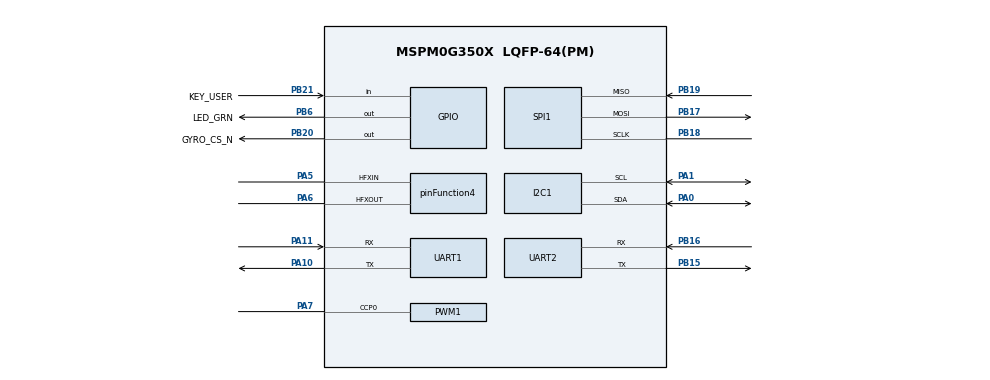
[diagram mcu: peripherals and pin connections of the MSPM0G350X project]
/**
 *
 * @cliArgs --device "MSPM0G350X" --part "Default" --package "LQFP-64(PM)" --product "mspm0_sdk@2.10.00.04"
 * @versions {"tool":"1.28.0+4712"}
 */

/**
 * Import the modules used in this configuration.
 */
const GPIO          = scripting.addModule("/ti/driverlib/GPIO", {}, false);
const GPIO1         = GPIO.addInstance();
const GPIO2         = GPIO.addInstance();
const GPIO3         = GPIO.addInstance();
const I2C           = scripting.addModule("/ti/driverlib/I2C", {}, false);
const I2C1          = I2C.addInstance();
const MATHACL       = scripting.addModule("/ti/driverlib/MATHACL");
const PWM           = scripting.addModule("/ti/driverlib/PWM", {}, false);
const PWM1          = PWM.addInstance();
const SPI           = scripting.addModule("/ti/driverlib/SPI", {}, false);
const SPI1          = SPI.addInstance();
const SYSCTL        = scripting.addModule("/ti/driverlib/SYSCTL");
const SYSTICK       = scripting.addModule("/ti/driverlib/SYSTICK");
const UART          = scripting.addModule("/ti/driverlib/UART", {}, false);
const UART1         = UART.addInstance();
const UART2         = UART.addInstance();
const ProjectConfig = scripting.addModule("/ti/project_config/ProjectConfig");

/**
 * Write custom configuration values to the imported modules.
 */
const divider9       = system.clockTree["UDIV"];
divider9.divideValue = 2;

const mux2       = system.clockTree["CANCLKMUX"];
mux2.inputSelect = "CANCLKMUX_PLLCLK1_OUT";

const mux4       = system.clockTree["EXHFMUX"];
mux4.inputSelect = "EXHFMUX_XTAL";

const mux8       = system.clockTree["HSCLKMUX"];
mux8.inputSelect = "HSCLKMUX_SYSPLL2X";

const mux10       = system.clockTree["MFPCLKMUX"];
mux10.inputSelect = "MFPCLKMUX_HFCLK";

const mux12       = system.clockTree["SYSPLLMUX"];
mux12.inputSelect = "zSYSPLLMUX_HFCLK";

const pinFunction4                        = system.clockTree["HFXT"];
pinFunction4.inputFreq                    = 40;
pinFunction4.enable                       = true;
pinFunction4.HFCLKMonitor                 = true;
pinFunction4.HFXTStartup                  = 255;
pinFunction4.peripheral.hfxInPin.$assign  = "PA5";
pinFunction4.peripheral.hfxOutPin.$assign = "PA6";

GPIO1.port                           = "PORTB";
GPIO1.$name                          = "GPIO_GRP_LEDS";
GPIO1.portSegment                    = "Lower";
GPIO1.associatedPins.create(2);
GPIO1.associatedPins[0].$name        = "LED_GRN";
GPIO1.associatedPins[0].initialValue = "SET";
GPIO1.associatedPins[0].ioStructure  = "SD";
GPIO1.associatedPins[0].assignedPin  = "6";
GPIO1.associatedPins[0].pin.$assign  = "PB6";
GPIO1.associatedPins[1].$name        = "LED_RED";
GPIO1.associatedPins[1].initialValue = "SET";
GPIO1.associatedPins[1].ioStructure  = "SD";
GPIO1.associatedPins[1].assignedPin  = "7";

const Board = scripting.addModule("/ti/driverlib/Board", {}, false);

GPIO2.port                          = "PORTB";
GPIO2.$name                         = "GPIO_GRP_KEY";
GPIO2.portSegment                   = "Upper";
GPIO2.associatedPins[0].$name       = "KEY_USER";
GPIO2.associatedPins[0].direction   = "INPUT";
GPIO2.associatedPins[0].interruptEn = true;
GPIO2.associatedPins[0].polarity    = "RISE_FALL";
GPIO2.associatedPins[0].assignedPin = "21";
GPIO2.associatedPins[0].pin.$assign = "PB21";

GPIO3.port                           = "PORTB";
GPIO3.$name                          = "GPIO_GRP_GYRO";
GPIO3.portSegment                    = "Upper";
GPIO3.associatedPins[0].$name        = "GYRO_CS_N";
GPIO3.associatedPins[0].initialValue = "SET";
GPIO3.associatedPins[0].assignedPin  = "20";
GPIO3.associatedPins[0].pin.$assign  = "PB20";

I2C1.$name                             = "I2C_TEMP";
I2C1.basicEnableController             = true;
I2C1.advControllerTXFIFOTRIG           = "BYTES_1";
I2C1.intController                     = ["ARBITRATION_LOST","NACK","RXFIFO_TRIGGER","RX_DONE","TX_DONE"];
I2C1.peripheral.$assign                = "I2C0";
I2C1.peripheral.sdaPin.$assign         = "PA0";
I2C1.peripheral.sclPin.$assign         = "PA1";
I2C1.sdaPinConfig.$name                = "ti_driverlib_gpio_GPIOPinGeneric0";
I2C1.sdaPinConfig.hideOutputInversion  = scripting.forceWrite(false);
I2C1.sdaPinConfig.onlyInternalResistor = scripting.forceWrite(false);
I2C1.sdaPinConfig.passedPeripheralType = scripting.forceWrite("Digital");
I2C1.sclPinConfig.$name                = "ti_driverlib_gpio_GPIOPinGeneric1";
I2C1.sclPinConfig.hideOutputInversion  = scripting.forceWrite(false);
I2C1.sclPinConfig.onlyInternalResistor = scripting.forceWrite(false);
I2C1.sclPinConfig.passedPeripheralType = scripting.forceWrite("Digital");

PWM1.$name                              = "PWM_OUTPUT";
PWM1.clockSource                        = "BUSCLK";
PWM1.clockDivider                       = 1;
PWM1.clockPrescale                      = 1;
PWM1.timerCount                         = 2000;
PWM1.pwmMode                            = "EDGE_ALIGN";
PWM1.ccIndex                            = [0];
PWM1.enableShadowLoad                   = false;
PWM1.timerStartTimer                    = false;
PWM1.peripheral.$assign                 = "TIMG8";
PWM1.peripheral.ccp0Pin.$assign         = "PA7";
PWM1.ccp0PinConfig.$name                = "ti_driverlib_gpio_GPIOPinGeneric10";
PWM1.PWM_CHANNEL_0.$name                = "ti_driverlib_pwm_PWMTimerCC0";
PWM1.PWM_CHANNEL_0.dutyCycle            = 0;

SPI1.$name                              = "SPI_GYRO";
SPI1.targetBitRate                      = 1000000;
SPI1.frameFormat                        = "MOTO3";
SPI1.chipSelect                         = [];
SPI1.sclkPinConfig.$name                = "ti_driverlib_gpio_GPIOPinGeneric2";
SPI1.sclkPinConfig.direction            = scripting.forceWrite("OUTPUT");
SPI1.sclkPinConfig.onlyInternalResistor = scripting.forceWrite(false);
SPI1.sclkPinConfig.passedPeripheralType = scripting.forceWrite("Digital");
SPI1.mosiPinConfig.$name                = "ti_driverlib_gpio_GPIOPinGeneric3";
SPI1.mosiPinConfig.direction            = scripting.forceWrite("OUTPUT");
SPI1.mosiPinConfig.hideOutputInversion  = scripting.forceWrite(false);
SPI1.mosiPinConfig.onlyInternalResistor = scripting.forceWrite(false);
SPI1.mosiPinConfig.passedPeripheralType = scripting.forceWrite("Digital");
SPI1.misoPinConfig.$name                = "ti_driverlib_gpio_GPIOPinGeneric4";
SPI1.misoPinConfig.onlyInternalResistor = scripting.forceWrite(false);
SPI1.misoPinConfig.passedPeripheralType = scripting.forceWrite("Digital");
SPI1.misoPinConfig.enableConfig         = true;
SPI1.misoPinConfig.internalResistor     = "PULL_UP";
SPI1.peripheral.$assign                 = "SPI0";
SPI1.peripheral.sclkPin.$assign         = "PB18";
SPI1.peripheral.mosiPin.$assign         = "PB17";
SPI1.peripheral.misoPin.$assign         = "PB19";

SYSCTL.clockTreeEn           = true;
SYSCTL.forceDefaultClkConfig = true;
SYSCTL.validateClkStatus     = true;

SYSTICK.periodEnable    = true;
SYSTICK.period          = 80000;
SYSTICK.interruptEnable = true;
SYSTICK.systickEnable   = true;

UART1.$name                             = "UART_TYPEC";
UART1.enableFIFO                        = true;
UART1.targetBaudRate                    = 115200;
UART1.enabledInterrupts                 = ["DMA_DONE_RX","DMA_DONE_TX"];
UART1.enabledDMARXTriggers              = "DL_UART_DMA_INTERRUPT_RX";
UART1.enabledDMATXTriggers              = "DL_UART_DMA_INTERRUPT_TX";
UART1.rxFifoThreshold                   = "DL_UART_RX_FIFO_LEVEL_ONE_ENTRY";
UART1.peripheral.$assign                = "UART0";
UART1.peripheral.rxPin.$assign          = "PA11";
UART1.peripheral.txPin.$assign          = "PA10";
UART1.txPinConfig.$name                 = "ti_driverlib_gpio_GPIOPinGeneric6";
UART1.txPinConfig.direction             = scripting.forceWrite("OUTPUT");
UART1.txPinConfig.hideOutputInversion   = scripting.forceWrite(false);
UART1.txPinConfig.onlyInternalResistor  = scripting.forceWrite(false);
UART1.txPinConfig.passedPeripheralType  = scripting.forceWrite("Digital");
UART1.rxPinConfig.$name                 = "ti_driverlib_gpio_GPIOPinGeneric7";
UART1.rxPinConfig.hideOutputInversion   = scripting.forceWrite(false);
UART1.rxPinConfig.onlyInternalResistor  = scripting.forceWrite(false);
UART1.rxPinConfig.passedPeripheralType  = scripting.forceWrite("Digital");
UART1.DMA_CHANNEL_RX.$name              = "DMA_TYPEC_RX";
UART1.DMA_CHANNEL_RX.addressMode        = "f2b";
UART1.DMA_CHANNEL_RX.srcLength          = "BYTE";
UART1.DMA_CHANNEL_RX.dstLength          = "BYTE";
UART1.DMA_CHANNEL_RX.peripheral.$assign = "DMA_CH1";
UART1.DMA_CHANNEL_TX.$name              = "DMA_TYPEC_TX";
UART1.DMA_CHANNEL_TX.addressMode        = "b2f";
UART1.DMA_CHANNEL_TX.srcLength          = "BYTE";
UART1.DMA_CHANNEL_TX.dstLength          = "BYTE";
UART1.DMA_CHANNEL_TX.peripheral.$assign = "DMA_CH0";

UART2.$name                             = "UART_EXTERNAL";
UART2.enableFIFO                        = true;
UART2.targetBaudRate                    = 115200;
UART2.enabledInterrupts                 = ["DMA_DONE_RX","DMA_DONE_TX"];
UART2.enabledDMARXTriggers              = "DL_UART_DMA_INTERRUPT_RX";
UART2.enabledDMATXTriggers              = "DL_UART_DMA_INTERRUPT_TX";
UART2.rxFifoThreshold                   = "DL_UART_RX_FIFO_LEVEL_ONE_ENTRY";
UART2.peripheral.$assign                = "UART2";
UART2.peripheral.rxPin.$assign          = "PB16";
UART2.peripheral.txPin.$assign          = "PB15";
UART2.txPinConfig.$name                 = "ti_driverlib_gpio_GPIOPinGeneric8";
UART2.txPinConfig.direction             = scripting.forceWrite("OUTPUT");
UART2.txPinConfig.hideOutputInversion   = scripting.forceWrite(false);
UART2.txPinConfig.onlyInternalResistor  = scripting.forceWrite(false);
UART2.txPinConfig.passedPeripheralType  = scripting.forceWrite("Digital");
UART2.rxPinConfig.$name                 = "ti_driverlib_gpio_GPIOPinGeneric9";
UART2.rxPinConfig.hideOutputInversion   = scripting.forceWrite(false);
UART2.rxPinConfig.onlyInternalResistor  = scripting.forceWrite(false);
UART2.rxPinConfig.passedPeripheralType  = scripting.forceWrite("Digital");
UART2.DMA_CHANNEL_RX.$name              = "DMA_EXTERNAL_RX";
UART2.DMA_CHANNEL_RX.addressMode        = "f2b";
UART2.DMA_CHANNEL_RX.srcLength          = "BYTE";
UART2.DMA_CHANNEL_RX.dstLength          = "BYTE";
UART2.DMA_CHANNEL_RX.peripheral.$assign = "DMA_CH3";
UART2.DMA_CHANNEL_TX.$name              = "DMA_EXTERNAL_TX";
UART2.DMA_CHANNEL_TX.addressMode        = "b2f";
UART2.DMA_CHANNEL_TX.srcLength          = "BYTE";
UART2.DMA_CHANNEL_TX.dstLength          = "BYTE";
UART2.DMA_CHANNEL_TX.peripheral.$assign = "DMA_CH2";

ProjectConfig.genLibCMSIS = true;
ProjectConfig.compiler    = "gcc";

/**
 * Pinmux solution for unlocked pins/peripherals. This ensures that minor changes to the automatic solver in a future
 * version of the tool will not impact the pinmux you originally saw.  These lines can be completely deleted in order to
 * re-solve from scratch.
 */
pinFunction4.peripheral.$suggestSolution     = "SYSCTL";
GPIO1.associatedPins[1].pin.$suggestSolution = "PB7";
Board.peripheral.$suggestSolution            = "DEBUGSS";
Board.peripheral.swclkPin.$suggestSolution   = "PA20";
Board.peripheral.swdioPin.$suggestSolution   = "PA19";
